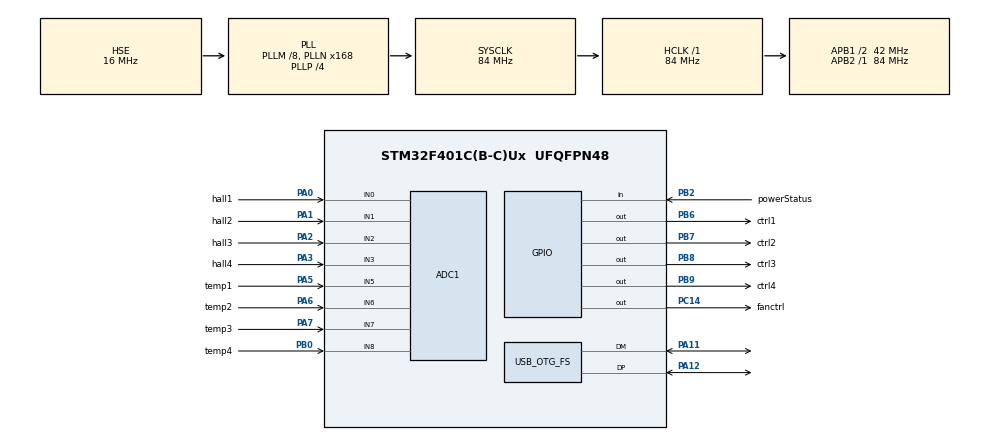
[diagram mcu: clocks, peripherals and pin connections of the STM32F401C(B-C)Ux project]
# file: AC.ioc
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ADC1.Channel-0\#ChannelRegularConversion=ADC_CHANNEL_0
ADC1.Channel-1\#ChannelRegularConversion=ADC_CHANNEL_1
ADC1.Channel-2\#ChannelRegularConversion=ADC_CHANNEL_2
ADC1.Channel-3\#ChannelRegularConversion=ADC_CHANNEL_3
ADC1.Channel-4\#ChannelRegularConversion=ADC_CHANNEL_8
ADC1.Channel-5\#ChannelRegularConversion=ADC_CHANNEL_7
ADC1.Channel-6\#ChannelRegularConversion=ADC_CHANNEL_6
ADC1.Channel-7\#ChannelRegularConversion=ADC_CHANNEL_5
ADC1.DMAContinuousRequests=ENABLE
ADC1.EOCSelection=ADC_EOC_SEQ_CONV
ADC1.ExternalTrigConv=ADC_EXTERNALTRIGCONV_T2_TRGO
ADC1.NbrOfConversion=8
ADC1.NbrOfConversionFlag=1
ADC1.Rank-0\#ChannelRegularConversion=1
ADC1.Rank-1\#ChannelRegularConversion=2
ADC1.Rank-2\#ChannelRegularConversion=3
ADC1.Rank-3\#ChannelRegularConversion=4
ADC1.Rank-4\#ChannelRegularConversion=5
ADC1.Rank-5\#ChannelRegularConversion=6
ADC1.Rank-6\#ChannelRegularConversion=7
ADC1.Rank-7\#ChannelRegularConversion=8
ADC1.SamplingTime-0\#ChannelRegularConversion=ADC_SAMPLETIME_144CYCLES
ADC1.SamplingTime-1\#ChannelRegularConversion=ADC_SAMPLETIME_144CYCLES
ADC1.SamplingTime-2\#ChannelRegularConversion=ADC_SAMPLETIME_144CYCLES
ADC1.SamplingTime-3\#ChannelRegularConversion=ADC_SAMPLETIME_144CYCLES
ADC1.SamplingTime-4\#ChannelRegularConversion=ADC_SAMPLETIME_144CYCLES
ADC1.SamplingTime-5\#ChannelRegularConversion=ADC_SAMPLETIME_144CYCLES
ADC1.SamplingTime-6\#ChannelRegularConversion=ADC_SAMPLETIME_144CYCLES
ADC1.SamplingTime-7\#ChannelRegularConversion=ADC_SAMPLETIME_144CYCLES
ADC1.ScanConvMode=ENABLE
ADC1.master=1
Dma.ADC1.0.Direction=DMA_PERIPH_TO_MEMORY
Dma.ADC1.0.FIFOMode=DMA_FIFOMODE_DISABLE
Dma.ADC1.0.Instance=DMA2_Stream0
Dma.ADC1.0.MemDataAlignment=DMA_MDATAALIGN_HALFWORD
Dma.ADC1.0.MemInc=DMA_MINC_ENABLE
Dma.ADC1.0.Mode=DMA_CIRCULAR
Dma.ADC1.0.PeriphDataAlignment=DMA_PDATAALIGN_HALFWORD
Dma.ADC1.0.PeriphInc=DMA_PINC_DISABLE
Dma.ADC1.0.Priority=DMA_PRIORITY_LOW
Dma.Request0=ADC1
IWDG.Prescaler=IWDG_PRESCALER_16
IWDG.Reload=1000
Mcu.Family=STM32F4
Mcu.Name=STM32F401C(B-C)Ux
Mcu.Package=UFQFPN48
NVIC.DMA2_Stream0_IRQn=true\:0\:0\:false\:false\:true\:false\:true\:true
NVIC.OTG_FS_IRQn=true\:0\:0\:false\:false\:true\:false\:true\:true
NVIC.PriorityGroup=NVIC_PRIORITYGROUP_4
PA0-WKUP.GPIO_Label=hall1
PA0-WKUP.Signal=SharedAnalog_PA0
PA1.GPIO_Label=hall2
PA1.Signal=ADCx_IN1
PA11.Mode=Device_Only
PA11.Signal=USB_OTG_FS_DM
PA12.Mode=Device_Only
PA12.Signal=USB_OTG_FS_DP
PA13.Mode=Serial_Wire
PA13.Signal=SYS_JTMS-SWDIO
PA14.Mode=Serial_Wire
PA14.Signal=SYS_JTCK-SWCLK
PA2.GPIO_Label=hall3
PA2.Signal=ADCx_IN2
PA3.GPIO_Label=hall4
PA3.Signal=ADCx_IN3
PA5.GPIO_Label=temp1
PA5.Signal=ADCx_IN5
PA6.GPIO_Label=temp2
PA6.Signal=SharedAnalog_PA6
PA7.GPIO_Label=temp3
PA7.Signal=ADCx_IN7
PB0.GPIO_Label=temp4
PB0.Signal=ADCx_IN8
PB2.GPIO_Label=powerStatus
PB2.Signal=GPIO_Input
PB6.GPIO_Label=ctrl1
PB6.Signal=GPIO_Output
PB7.GPIO_Label=ctrl2
PB7.Signal=GPIO_Output
PB8.GPIO_Label=ctrl3
PB8.Signal=GPIO_Output
PB9.GPIO_Label=ctrl4
PB9.Signal=GPIO_Output
PC14-OSC32_IN.GPIO_Label=fanctrl
PC14-OSC32_IN.Signal=GPIO_Output
PH0\ -\ OSC_IN.Mode=HSE-External-Oscillator
PH0\ -\ OSC_IN.Signal=RCC_OSC_IN
PH1\ -\ OSC_OUT.Mode=HSE-External-Oscillator
PH1\ -\ OSC_OUT.Signal=RCC_OSC_OUT
ProjectManager.HeapSize=0x600
ProjectManager.StackSize=0x400
ProjectManager.TargetToolchain=Makefile
RCC.48MHZClocksFreq_Value=48000000
RCC.AHBFreq_Value=84000000
RCC.APB1CLKDivider=RCC_HCLK_DIV2
RCC.APB1Freq_Value=42000000
RCC.APB1TimFreq_Value=84000000
RCC.APB2Freq_Value=84000000
RCC.APB2TimFreq_Value=84000000
RCC.CortexFreq_Value=84000000
RCC.HCLKFreq_Value=84000000
RCC.HSE_VALUE=16000000
RCC.HSI_VALUE=16000000
RCC.LSE_VALUE=32768
RCC.PLLM=8
RCC.PLLN=168
RCC.PLLP=RCC_PLLP_DIV4
RCC.PLLQ=7
RCC.SYSCLKFreq_VALUE=84000000
RCC.SYSCLKSource=RCC_SYSCLKSOURCE_PLLCLK
RCC.VCOOutputFreq_Value=336000000
SH.ADCx_IN1.0=ADC1_IN1,IN1
SH.ADCx_IN2.0=ADC1_IN2,IN2
SH.ADCx_IN3.0=ADC1_IN3,IN3
SH.ADCx_IN5.0=ADC1_IN5,IN5
SH.ADCx_IN7.0=ADC1_IN7,IN7
SH.ADCx_IN8.0=ADC1_IN8,IN8
SH.SharedAnalog_PA0.0=GPIO_Analog
SH.SharedAnalog_PA0.1=ADC1_IN0,IN0
SH.SharedAnalog_PA6.0=GPIO_Analog
SH.SharedAnalog_PA6.1=ADC1_IN6,IN6
TIM2.AutoReloadPreload=TIM_AUTORELOAD_PRELOAD_ENABLE
TIM2.Period=250-1
TIM2.Prescaler=84-1
TIM2.TIM_MasterOutputTrigger=TIM_TRGO_UPDATE
TIM2.TIM_MasterSlaveMode=TIM_MASTERSLAVEMODE_ENABLE
USB_DEVICE.CLASS_NAME_FS=CDC
USB_DEVICE.VirtualMode=Cdc
USB_DEVICE.VirtualModeFS=Cdc_FS
USB_OTG_FS.VirtualMode=Device_Only
VP_CRC_VS_CRC.Mode=CRC_Activate
VP_IWDG_VS_IWDG.Mode=IWDG_Activate
VP_TIM2_VS_ClockSourceINT.Mode=Internal
VP_USB_DEVICE_VS_USB_DEVICE_CDC_FS.Mode=CDC_FS
board=custom

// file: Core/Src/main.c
/* USER CODE BEGIN Header */
/**
 ******************************************************************************
 * @file           : main.c
 * @brief          : Main program body
 ******************************************************************************
 *
 * ToDo Code Flow Overview (make functions and comments)
 *
 ******************************************************************************
 */
/* USER CODE END Header */
#include "main.h"
#include "usb_device.h"

/* USER CODE BEGIN Includes */
#include "CAProtocolStm.h"
#include "ACBoard.h"
/* USER CODE END Includes */

ADC_HandleTypeDef hadc1;
DMA_HandleTypeDef hdma_adc1;

CRC_HandleTypeDef hcrc;

IWDG_HandleTypeDef hiwdg;

TIM_HandleTypeDef htim2;

void SystemClock_Config(void);
static void MX_GPIO_Init(void);
static void MX_DMA_Init(void);
static void MX_ADC1_Init(void);
static void MX_TIM2_Init(void);
static void MX_IWDG_Init(void);
static void MX_CRC_Init(void);

int main(void)
{

  /* MCU Configuration--------------------------------------------------------*/

  /* Reset of all peripherals, Initializes the Flash interface and the Systick. */
  HAL_Init();

  /* Configure the system clock */
  SystemClock_Config();

  /* USER CODE BEGIN SysInit */
  const char *bootMsg = CAonBoot();
  /* USER CODE END SysInit */

  /* Initialize all configured peripherals */
  MX_GPIO_Init();
  MX_DMA_Init();
  MX_USB_DEVICE_Init();
  MX_ADC1_Init();
  MX_TIM2_Init();
  MX_IWDG_Init();
  MX_CRC_Init();
  /* USER CODE BEGIN 2 */
  // Initialization of timers takes time which will force a wwdg reset,
  // hence disable timers momentarily during setup.
  __HAL_RCC_WWDG_CLK_DISABLE();
  ACBoardInit(&hadc1, &hcrc, bootMsg);
  HAL_TIM_Base_Start_IT(&htim2);
  __HAL_RCC_WWDG_CLK_ENABLE();
  /* USER CODE END 2 */

  /* Infinite loop */
  /* USER CODE BEGIN WHILE */
    while (1)
    {
      HAL_IWDG_Refresh(&hiwdg);
      ACBoardLoop(bootMsg);
    /* USER CODE END WHILE */

    }
}

void SystemClock_Config(void)
{
  RCC_OscInitTypeDef RCC_OscInitStruct = {0};
  RCC_ClkInitTypeDef RCC_ClkInitStruct = {0};

  /** Configure the main internal regulator output voltage
  */
  __HAL_RCC_PWR_CLK_ENABLE();
  __HAL_PWR_VOLTAGESCALING_CONFIG(PWR_REGULATOR_VOLTAGE_SCALE2);

  /** Initializes the RCC Oscillators according to the specified parameters
  * in the RCC_OscInitTypeDef structure.
  */
  RCC_OscInitStruct.OscillatorType = RCC_OSCILLATORTYPE_LSI|RCC_OSCILLATORTYPE_HSE;
  RCC_OscInitStruct.HSEState = RCC_HSE_ON;
  RCC_OscInitStruct.LSIState = RCC_LSI_ON;
  RCC_OscInitStruct.PLL.PLLState = RCC_PLL_ON;
  RCC_OscInitStruct.PLL.PLLSource = RCC_PLLSOURCE_HSE;
  RCC_OscInitStruct.PLL.PLLM = 8;
  RCC_OscInitStruct.PLL.PLLN = 168;
  RCC_OscInitStruct.PLL.PLLP = RCC_PLLP_DIV4;
  RCC_OscInitStruct.PLL.PLLQ = 7;
  if (HAL_RCC_OscConfig(&RCC_OscInitStruct) != HAL_OK)
  {
    Error_Handler();
  }

  /** Initializes the CPU, AHB and APB buses clocks
  */
  RCC_ClkInitStruct.ClockType = RCC_CLOCKTYPE_HCLK|RCC_CLOCKTYPE_SYSCLK
                              |RCC_CLOCKTYPE_PCLK1|RCC_CLOCKTYPE_PCLK2;
  RCC_ClkInitStruct.SYSCLKSource = RCC_SYSCLKSOURCE_PLLCLK;
  RCC_ClkInitStruct.AHBCLKDivider = RCC_SYSCLK_DIV1;
  RCC_ClkInitStruct.APB1CLKDivider = RCC_HCLK_DIV2;
  RCC_ClkInitStruct.APB2CLKDivider = RCC_HCLK_DIV1;

  if (HAL_RCC_ClockConfig(&RCC_ClkInitStruct, FLASH_LATENCY_2) != HAL_OK)
  {
    Error_Handler();
  }
}

static void MX_ADC1_Init(void)
{

  ADC_ChannelConfTypeDef sConfig = {0};

  /** Configure the global features of the ADC (Clock, Resolution, Data Alignment and number of conversion)
  */
  hadc1.Instance = ADC1;
  hadc1.Init.ClockPrescaler = ADC_CLOCK_SYNC_PCLK_DIV4;
  hadc1.Init.Resolution = ADC_RESOLUTION_12B;
  hadc1.Init.ScanConvMode = ENABLE;
  hadc1.Init.ContinuousConvMode = DISABLE;
  hadc1.Init.DiscontinuousConvMode = DISABLE;
  hadc1.Init.ExternalTrigConvEdge = ADC_EXTERNALTRIGCONVEDGE_RISING;
  hadc1.Init.ExternalTrigConv = ADC_EXTERNALTRIGCONV_T2_TRGO;
  hadc1.Init.DataAlign = ADC_DATAALIGN_RIGHT;
  hadc1.Init.NbrOfConversion = 8;
  hadc1.Init.DMAContinuousRequests = ENABLE;
  hadc1.Init.EOCSelection = ADC_EOC_SEQ_CONV;
  if (HAL_ADC_Init(&hadc1) != HAL_OK)
  {
    Error_Handler();
  }

  /** Configure for the selected ADC regular channel its corresponding rank in the sequencer and its sample time.
  */
  sConfig.Channel = ADC_CHANNEL_0;
  sConfig.Rank = 1;
  sConfig.SamplingTime = ADC_SAMPLETIME_144CYCLES;
  if (HAL_ADC_ConfigChannel(&hadc1, &sConfig) != HAL_OK)
  {
    Error_Handler();
  }

  /** Configure for the selected ADC regular channel its corresponding rank in the sequencer and its sample time.
  */
  sConfig.Channel = ADC_CHANNEL_1;
  sConfig.Rank = 2;
  if (HAL_ADC_ConfigChannel(&hadc1, &sConfig) != HAL_OK)
  {
    Error_Handler();
  }

  /** Configure for the selected ADC regular channel its corresponding rank in the sequencer and its sample time.
  */
  sConfig.Channel = ADC_CHANNEL_2;
  sConfig.Rank = 3;
  if (HAL_ADC_ConfigChannel(&hadc1, &sConfig) != HAL_OK)
  {
    Error_Handler();
  }

  /** Configure for the selected ADC regular channel its corresponding rank in the sequencer and its sample time.
  */
  sConfig.Channel = ADC_CHANNEL_3;
  sConfig.Rank = 4;
  if (HAL_ADC_ConfigChannel(&hadc1, &sConfig) != HAL_OK)
  {
    Error_Handler();
  }

  /** Configure for the selected ADC regular channel its corresponding rank in the sequencer and its sample time.
  */
  sConfig.Channel = ADC_CHANNEL_8;
  sConfig.Rank = 5;
  if (HAL_ADC_ConfigChannel(&hadc1, &sConfig) != HAL_OK)
  {
    Error_Handler();
  }

  /** Configure for the selected ADC regular channel its corresponding rank in the sequencer and its sample time.
  */
  sConfig.Channel = ADC_CHANNEL_7;
  sConfig.Rank = 6;
  if (HAL_ADC_ConfigChannel(&hadc1, &sConfig) != HAL_OK)
  {
    Error_Handler();
  }

  /** Configure for the selected ADC regular channel its corresponding rank in the sequencer and its sample time.
  */
  sConfig.Channel = ADC_CHANNEL_6;
  sConfig.Rank = 7;
  if (HAL_ADC_ConfigChannel(&hadc1, &sConfig) != HAL_OK)
  {
    Error_Handler();
  }

  /** Configure for the selected ADC regular channel its corresponding rank in the sequencer and its sample time.
  */
  sConfig.Channel = ADC_CHANNEL_5;
  sConfig.Rank = 8;
  if (HAL_ADC_ConfigChannel(&hadc1, &sConfig) != HAL_OK)
  {
    Error_Handler();
  }

}

static void MX_CRC_Init(void)
{

  hcrc.Instance = CRC;
  if (HAL_CRC_Init(&hcrc) != HAL_OK)
  {
    Error_Handler();
  }

}

static void MX_IWDG_Init(void)
{

  hiwdg.Instance = IWDG;
  hiwdg.Init.Prescaler = IWDG_PRESCALER_16;
  hiwdg.Init.Reload = 1000;
  if (HAL_IWDG_Init(&hiwdg) != HAL_OK)
  {
    Error_Handler();
  }

}

static void MX_TIM2_Init(void)
{

  TIM_ClockConfigTypeDef sClockSourceConfig = {0};
  TIM_MasterConfigTypeDef sMasterConfig = {0};

  htim2.Instance = TIM2;
  htim2.Init.Prescaler = 84-1;
  htim2.Init.CounterMode = TIM_COUNTERMODE_UP;
  htim2.Init.Period = 250-1;
  htim2.Init.ClockDivision = TIM_CLOCKDIVISION_DIV1;
  htim2.Init.AutoReloadPreload = TIM_AUTORELOAD_PRELOAD_ENABLE;
  if (HAL_TIM_Base_Init(&htim2) != HAL_OK)
  {
    Error_Handler();
  }
  sClockSourceConfig.ClockSource = TIM_CLOCKSOURCE_INTERNAL;
  if (HAL_TIM_ConfigClockSource(&htim2, &sClockSourceConfig) != HAL_OK)
  {
    Error_Handler();
  }
  sMasterConfig.MasterOutputTrigger = TIM_TRGO_UPDATE;
  sMasterConfig.MasterSlaveMode = TIM_MASTERSLAVEMODE_ENABLE;
  if (HAL_TIMEx_MasterConfigSynchronization(&htim2, &sMasterConfig) != HAL_OK)
  {
    Error_Handler();
  }

}

static void MX_DMA_Init(void)
{

  /* DMA controller clock enable */
  __HAL_RCC_DMA2_CLK_ENABLE();

  /* DMA interrupt init */
  /* DMA2_Stream0_IRQn interrupt configuration */
  HAL_NVIC_SetPriority(DMA2_Stream0_IRQn, 0, 0);
  HAL_NVIC_EnableIRQ(DMA2_Stream0_IRQn);

}

static void MX_GPIO_Init(void)
{
  GPIO_InitTypeDef GPIO_InitStruct = {0};

  /* GPIO Ports Clock Enable */
  __HAL_RCC_GPIOC_CLK_ENABLE();
  __HAL_RCC_GPIOH_CLK_ENABLE();
  __HAL_RCC_GPIOA_CLK_ENABLE();
  __HAL_RCC_GPIOB_CLK_ENABLE();

  /*Configure GPIO pin Output Level */
  HAL_GPIO_WritePin(fanctrl_GPIO_Port, fanctrl_Pin, GPIO_PIN_RESET);

  /*Configure GPIO pin Output Level */
  HAL_GPIO_WritePin(GPIOB, ctrl1_Pin|ctrl2_Pin|ctrl3_Pin|ctrl4_Pin, GPIO_PIN_RESET);

  /*Configure GPIO pin : fanctrl_Pin */
  GPIO_InitStruct.Pin = fanctrl_Pin;
  GPIO_InitStruct.Mode = GPIO_MODE_OUTPUT_PP;
  GPIO_InitStruct.Pull = GPIO_NOPULL;
  GPIO_InitStruct.Speed = GPIO_SPEED_FREQ_LOW;
  HAL_GPIO_Init(fanctrl_GPIO_Port, &GPIO_InitStruct);

  /*Configure GPIO pin : powerStatus_Pin */
  GPIO_InitStruct.Pin = powerStatus_Pin;
  GPIO_InitStruct.Mode = GPIO_MODE_INPUT;
  GPIO_InitStruct.Pull = GPIO_NOPULL;
  HAL_GPIO_Init(powerStatus_GPIO_Port, &GPIO_InitStruct);

  /*Configure GPIO pins : ctrl1_Pin ctrl2_Pin ctrl3_Pin ctrl4_Pin */
  GPIO_InitStruct.Pin = ctrl1_Pin|ctrl2_Pin|ctrl3_Pin|ctrl4_Pin;
  GPIO_InitStruct.Mode = GPIO_MODE_OUTPUT_PP;
  GPIO_InitStruct.Pull = GPIO_NOPULL;
  GPIO_InitStruct.Speed = GPIO_SPEED_FREQ_LOW;
  HAL_GPIO_Init(GPIOB, &GPIO_InitStruct);

}

void Error_Handler(void)
{
	__disable_irq();
	while (1) {
	}
}
